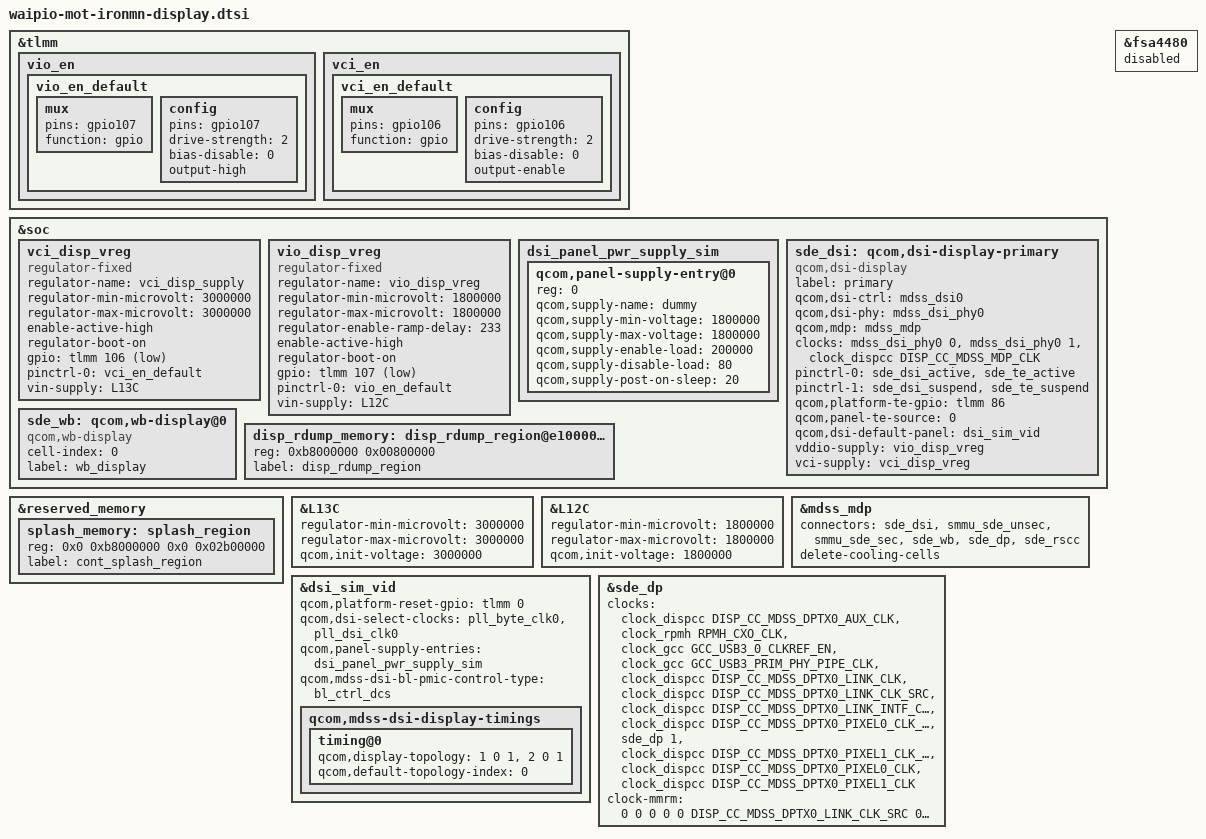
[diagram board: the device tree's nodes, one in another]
/*
   this is original from waipio-sde-display-hiphi-common-base.dtsi
*/
#include <dt-bindings/clock/qcom,gcc-waipio.h>
#include <dt-bindings/clock/qcom,rpmh.h>
#include "waipio-sde-display-pinctrl.dtsi"
#include <dt-bindings/clock/qcom,dispcc-waipio.h>
#include "dsi-panel-sim-video.dtsi"

&tlmm {
	vio_en {
		vio_en_default: vio_en_default {
			mux {
				pins = "gpio107";
				function = "gpio";
			};

			config {
				pins = "gpio107";
				drive-strength = <2>;   /* 2 mA */
				bias-disable = <0>;   /* no pull */
				output-high;
			};
		};
	};
	vci_en {
		vci_en_default: vci_en_default {
			mux {
				pins = "gpio106";
				function = "gpio";
			};

			config {
				pins = "gpio106";
				drive-strength = <2>;   /* 2 mA */
				bias-disable = <0>;   /* no pull */
				output-enable;
			};
		};
	};
};

&soc {
	vci_disp_vreg:  vci_disp_vreg{
		compatible = "regulator-fixed";
		regulator-name = "vci_disp_supply";
		regulator-min-microvolt = <3000000>;
		regulator-max-microvolt = <3000000>;
		enable-active-high;
		regulator-boot-on;

		gpio = <&tlmm 106 1>;
		pinctrl-names = "default";
		pinctrl-0 = <&vci_en_default>;
		vin-supply = <&L13C>;
	};

	vio_disp_vreg: vio_disp_vreg{
		compatible = "regulator-fixed";
		regulator-name = "vio_disp_vreg";
		regulator-min-microvolt = <1800000>;
		regulator-max-microvolt = <1800000>;
		regulator-enable-ramp-delay = <233>;
		enable-active-high;
		regulator-boot-on;

		gpio = <&tlmm 107 1>;
		pinctrl-names = "default";
		pinctrl-0 = <&vio_en_default>;
		vin-supply = <&L12C>;
	};

	dsi_panel_pwr_supply_sim: dsi_panel_pwr_supply_sim {
		#address-cells = <1>;
		#size-cells = <0>;

		qcom,panel-supply-entry@0 {
			reg = <0>;
			qcom,supply-name = "dummy";
			qcom,supply-min-voltage = <1800000>;
			qcom,supply-max-voltage = <1800000>;
			qcom,supply-enable-load = <200000>;
			qcom,supply-disable-load = <80>;
			qcom,supply-post-on-sleep = <20>;
		};
	};

	sde_dsi: qcom,dsi-display-primary {
		compatible = "qcom,dsi-display";
		label = "primary";

		qcom,dsi-ctrl = <&mdss_dsi0>;
		qcom,dsi-phy = <&mdss_dsi_phy0>;

		qcom,mdp = <&mdss_mdp>;

		clocks = <&mdss_dsi_phy0 0>,
				<&mdss_dsi_phy0 1>,
			 <&clock_dispcc DISP_CC_MDSS_MDP_CLK>;
		clock-names = "pll_byte_clk0", "pll_dsi_clk0",
			"mdp_core_clk";

		pinctrl-names = "panel_active", "panel_suspend";
		pinctrl-0 = <&sde_dsi_active &sde_te_active>;
		pinctrl-1 = <&sde_dsi_suspend &sde_te_suspend>;

		qcom,platform-te-gpio = <&tlmm 86 0>;
		qcom,panel-te-source = <0>;

		qcom,dsi-default-panel = <&dsi_sim_vid>;

		vddio-supply = <&vio_disp_vreg>;
		vci-supply = <&vci_disp_vreg>;
	};

	sde_wb: qcom,wb-display@0 {
		compatible = "qcom,wb-display";
		cell-index = <0>;
		label = "wb_display";
	};

	disp_rdump_memory: disp_rdump_region@e1000000 {
		reg = <0xb8000000 0x00800000>;
		label = "disp_rdump_region";
	};

};

&reserved_memory {
	splash_memory: splash_region {
		reg = <0x0 0xb8000000 0x0 0x02b00000>;
		label = "cont_splash_region";
	};
};
&L13C {
	regulator-min-microvolt = <3000000>;
	regulator-max-microvolt = <3000000>;
	qcom,init-voltage = <3000000>;
};

&L12C {
	regulator-min-microvolt = <1800000>;
	regulator-max-microvolt = <1800000>;
	qcom,init-voltage = <1800000>;
};

&mdss_mdp {
	connectors = <&sde_dsi &smmu_sde_unsec &smmu_sde_sec &sde_wb &sde_dp &sde_rscc>;
	delete-cooling-cells;
};

&dsi_sim_vid {
	qcom,platform-reset-gpio = <&tlmm 0 0>;
	qcom,dsi-select-clocks = "pll_byte_clk0", "pll_dsi_clk0";
	qcom,panel-supply-entries = <&dsi_panel_pwr_supply_sim>;
	qcom,mdss-dsi-bl-pmic-control-type = "bl_ctrl_dcs";
	qcom,mdss-dsi-display-timings {
		timing@0 {
			qcom,display-topology = <1 0 1>,
						<2 0 1>;
			qcom,default-topology-index = <0>;
		};
	};
};

&sde_dsi {
};
&fsa4480 {
	status = "disabled";
};

&sde_dp {
	#clock-cells = <1>;
	clocks =  <&clock_dispcc DISP_CC_MDSS_DPTX0_AUX_CLK>,
		<&clock_rpmh RPMH_CXO_CLK>,
		<&clock_gcc GCC_USB3_0_CLKREF_EN>,
		<&clock_gcc GCC_USB3_PRIM_PHY_PIPE_CLK>,
		<&clock_dispcc DISP_CC_MDSS_DPTX0_LINK_CLK>,
		<&clock_dispcc DISP_CC_MDSS_DPTX0_LINK_CLK_SRC>,
		<&clock_dispcc DISP_CC_MDSS_DPTX0_LINK_INTF_CLK>,
		<&clock_dispcc DISP_CC_MDSS_DPTX0_PIXEL0_CLK_SRC>,
		<&sde_dp 1>,
		<&clock_dispcc DISP_CC_MDSS_DPTX0_PIXEL1_CLK_SRC>,
		<&clock_dispcc DISP_CC_MDSS_DPTX0_PIXEL0_CLK>,
		<&clock_dispcc DISP_CC_MDSS_DPTX0_PIXEL1_CLK>;
	clock-names = "core_aux_clk", "rpmh_cxo_clk", "core_usb_ref_clk_src",
		"core_usb_pipe_clk", "link_clk", "link_clk_src", "link_iface_clk",
		"pixel_clk_rcg", "pixel_parent", "pixel1_clk_rcg",
		"strm0_pixel_clk", "strm1_pixel_clk";
	clock-mmrm = <0 0 0 0 0 DISP_CC_MDSS_DPTX0_LINK_CLK_SRC 0 0 0 0 0 0>;
};
